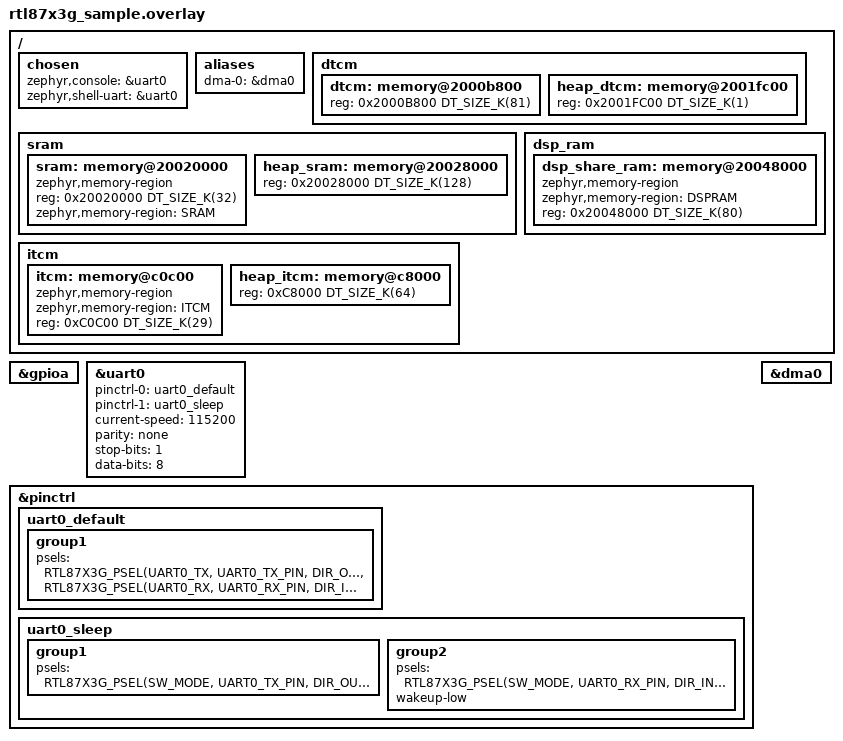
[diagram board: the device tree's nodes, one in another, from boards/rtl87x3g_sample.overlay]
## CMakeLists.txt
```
#
# Copyright (c) 2026, Realtek Semiconductor Corporation
#
# SPDX-License-Identifier: LicenseRef-Realtek-5-Clause
#

message(STATUS "CMAKELIST FOLDER: ${CMAKE_CURRENT_SOURCE_DIR}")

cmake_minimum_required(VERSION 3.20.0)

#===========version generation===========
include(${CMAKE_CURRENT_SOURCE_DIR}/../../cmake/version_generate.cmake)
generate_version()
#===========version generation===========
#===========post build===========
# post build should be called before find_package
include(${CMAKE_CURRENT_SOURCE_DIR}/../../cmake/post_build.cmake)
rtk_post_build()
#===========post build===========

find_package(Zephyr REQUIRED HINTS $ENV{ZEPHYR_BASE})
project(lea_cap_acceptor)

FILE(GLOB app_sources src/*.c)
target_sources(app PRIVATE
  ${app_sources}
  )

set(sources 
   ${ZEPHYR_REALTEK_APP_MODULE_DIR}/subsys/bluetooth/gatt_client/bt_ext_ftl.c
   ${ZEPHYR_REALTEK_APP_MODULE_DIR}/subsys/bluetooth/gatt_client/gattc_tbl_storage.c
   )
   
set(headers 
    #header files from app
	src/
    #header files from libs
    ${ZEPHYR_REALTEK_APP_MODULE_DIR}/subsys/bluetooth/gatt_client
    )

foreach(header ${headers})
    if(EXISTS ${header})
        zephyr_include_directories(${header})
    else()
        message(FATAL_ERROR "header file directory does not exist: ${header}. Current cmakelist: ${CMAKE_CURRENT_SOURCE_DIR}")
    endif()
endforeach()

foreach(src ${sources})
    if(EXISTS ${src})
        target_sources(app PRIVATE ${src})
    else()
        message(FATAL_ERROR "source file does not exist: ${src}. Current cmakelist: ${CMAKE_CURRENT_SOURCE_DIR}")
    endif()
endforeach()

target_precompile_headers(app PUBLIC 
	          ${CMAKE_CURRENT_SOURCE_DIR}/src/app_lea_cap_acc_flags.h
			  )
    
target_include_directories(app PRIVATE src)
```

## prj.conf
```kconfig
# nothing here
CONFIG_REALTEK_SUBSYS_BLE_MGR=y
CONFIG_REALTEK_SUBSYS_SYSM=y
CONFIG_REALTEK_SUBSYS_BLE_AUDIO=y

# Network shell
CONFIG_SERIAL=y
CONFIG_UART_CONSOLE=y
CONFIG_UART_INTERRUPT_DRIVEN=y
CONFIG_UART_ASYNC_API=y
CONFIG_SHELL=y
CONFIG_SHELL_BACKEND_SERIAL=y
CONFIG_LOG_RTK=n
CONFIG_PRINTK=y
CONFIG_HEAP_MEM_POOL_SIZE=1024
CONFIG_CONSOLE=y
#CONFIG_STDOUT_CONSOLE=y

#CONFIG_UART_SHELL_ON_DEV_NAME="UART_2"
#CONFIG_SHELL_PROMPT_UART="uart:~$ "
```

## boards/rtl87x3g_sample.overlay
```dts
/*
 * Copyright(c) 2024, Realtek Semiconductor Corporation.
 *
 * SPDX-License-Identifier: Apache-2.0
 */

#include <zephyr/dt-bindings/gpio/realtek-rtl87x3g-gpio.h>
#include <dt-bindings/pinctrl/rtl87x3g-pinctrl.h>
#include <dt-bindings/input/input-event-codes.h>
#include "../board.h"

&gpioa {
	status = "okay";
};

/ {
    chosen {
        zephyr,console = &uart0;
        zephyr,shell-uart = &uart0;
    };
};

/**
#define GDMA_Handshake_UART0_TX                                     (0)
#define GDMA_Handshake_UART0_RX                                     (1)
#define GDMA_Handshake_UART2_TX                                     (2)
#define GDMA_Handshake_UART2_RX                                     (3)
#define GDMA_Handshake_UART3_TX                                     (48)
#define GDMA_Handshake_UART3_RX                                     (49)
#define GDMA_Handshake_UART4_TX                                     (50)
#define GDMA_Handshake_UART4_RX                                     (51)
#define GDMA_Handshake_UART5_TX                                     (52)
#define GDMA_Handshake_UART5_RX                                     (53)
*/

&uart0 {
	pinctrl-0 = <&uart0_default>;
	pinctrl-1 = <&uart0_sleep>;
	pinctrl-names = "default", "sleep";
	status = "okay";
	current-speed = <115200>;
	parity = "none";
	stop-bits = "1";
	data-bits = <8>;
	//dmas = <&dma0 2 3 0xa>, <&dma0 3 2 0x10021>;
	//dma-names = "rx", "tx";
};

&pinctrl
{
	uart0_default:uart0_default {
		group1 {
			psels = <RTL87X3G_PSEL(UART0_TX, UART0_TX_PIN, DIR_OUT, DRV_HIGH, PULL_UP)>,
			<RTL87X3G_PSEL(UART0_RX, UART0_RX_PIN, DIR_IN, DRV_HIGH, PULL_UP)>;
		};
	};

	uart0_sleep:uart0_sleep {
		group1 {
			psels = <RTL87X3G_PSEL(SW_MODE, UART0_TX_PIN, DIR_OUT, DRV_HIGH, PULL_UP)>;
		};
		group2 {
			psels = <RTL87X3G_PSEL(SW_MODE, UART0_RX_PIN, DIR_IN, DRV_HIGH, PULL_UP)>;
			wakeup-low;
		};
	};
};

&dma0 {
	status = "okay";
};

&gpioa {
	status = "okay";
};

/*delete-node only support nodes with lable */
/delete-node/ &dtcm;
/delete-node/ &heap_dtcm;
/delete-node/ &sram;
/delete-node/ &heap_sram;
/delete-node/ &itcm;
/delete-node/ &heap_itcm;
/delete-node/ &dsp_share_ram;

/ {
	aliases {
		dma-0 = &dma0;
    };

	/* DTCM addr: 0x20000000~0x20020000, total size: 128KByte.
	 * The front 46Kbyte was taken by RTK internal.
	 * If users wants to increase global variables and zephyr static heap,
	 * please follow the steps:
	 * 1. increase dtcm size value "reg = <0x2000B800 DT_SIZE_K(NEW_SIZE)>"
	 * 2. modify heap_dtcm addr label "heap_dtcm: memory@NEW_ADDR"
	 * 3. modify heap_dtcm reg addr "reg = <NEW_ADDR DT_SIZE_K(NEW_SIZE)>"
	 * 4. decrease heap_dtcm size value "reg = <NEW_ADDR DT_SIZE_K(NEW_SIZE)>"
	 * Warning:
	 * 1. the dtcm address should NOT modified!
	 * 2. the dtcm plus heap_dtcm size should NOT exceed 82KByte!
	 */
	dtcm {
		dtcm: memory@2000b800 {
			device_type = "dtcm region";
			reg = <0x2000B800 DT_SIZE_K(81)>;
		};
		heap_dtcm: memory@2001fc00 {
			device_type = "heap dtcm region";
			reg = <0x2001FC00 DT_SIZE_K(1)>;
		};
	};
	/* sram addr: 0x20020000~0x20048000, total size: 160KByte.
	 * call zephyr_code_relocate(FILES xxx.x LOCATION SRAM) at cmakelist could relocate variables on sram.
	 * for more information, please refer to https://docs.zephyrproject.org/latest/kernel/code-relocation.html
	 * If users wants to increase sram size, please follow the steps:
	 * 1. increase sram size value "reg = <0x20020000 DT_SIZE_K(NEW_SIZE)>"
	 * 2. modify heap_sram addr label "heap_sram: memory@NEW_ADDR"
	 * 3. modify heap_sram reg addr "reg = <NEW_ADDR DT_SIZE_K(NEW_SIZE)>"
	 * 4. decrease heap_sram size value "reg = <NEW_ADDR DT_SIZE_K(NEW_SIZE)>"
	 * Warning:
	 * 1. the sram address should NOT modified!
	 * 2. the sram plus heap_sram size should NOT exceed 160KByte!
	 */
	sram {
		sram: memory@20020000 {
			device_type = "sram region";
			compatible = "zephyr,memory-region", "mmio-sram";
			reg = <0x20020000 DT_SIZE_K(32)>;
			zephyr,memory-region = "SRAM";
		};
		heap_sram: memory@20028000 {
			device_type = "heap sram region";
			reg = <0x20028000 DT_SIZE_K(128)>;
		};
	};

	itcm {
		itcm: memory@c0c00 {
			device_type = "itcm region";
			compatible = "zephyr,memory-region", "arm,itcm";
			zephyr,memory-region = "ITCM";
			reg = <0xC0C00 DT_SIZE_K(29)>;
		};
		heap_itcm: memory@c8000 {
			device_type = "heap itcm region";
			reg = <0xC8000 DT_SIZE_K(64)>;
		};
	};

	dsp_ram {
		dsp_share_ram: memory@20048000 {
			compatible = "zephyr,memory-region";
			device_type = "dsp_share_ram region";
			zephyr,memory-region = "DSPRAM";
			reg = <0x20048000 DT_SIZE_K(80)>;
		};
	};

};
```

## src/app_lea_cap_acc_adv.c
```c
/*
 * Copyright (c) 2026, Realtek Semiconductor Corporation
 *
 * SPDX-License-Identifier: LicenseRef-Realtek-5-Clause
 */

/*============================================================================*
 *                              Header Files
 *============================================================================*/
#include <string.h>
#include "trace.h"
#include "gatt.h"
#include "app_shell_cmd.h"
#include "ble_ext_adv.h"
#include "app_lea_cap_acc_adv.h"
#include "app_lea_cap_acc_main.h"
#include "csis_def.h"
#include "csis_rsi.h"
#include "ascs_def.h"
#include "cap.h"
#include "bass_def.h"

#define LE_EXT_TEST_ADV_DATA_LEN                    100

uint8_t app_ext_adv_handle;

uint16_t le_ext_adv_len = 3;
uint16_t le_ext_adv_flag = 0;

uint8_t ext_adv_data[LE_EXT_TEST_ADV_DATA_LEN] =
{
    /* Flags */
    0x02,             /* length */
    GAP_ADTYPE_FLAGS, /* type="Flags" */
    GAP_ADTYPE_FLAGS_LIMITED | GAP_ADTYPE_FLAGS_BREDR_NOT_SUPPORTED,
    //GAP_ADTYPE_FLAGS_LIMITED | GAP_ADTYPE_FLAGS_SIMULTANEOUS_LE_BREDR_CONTROLLER |GAP_ADTYPE_FLAGS_SIMULTANEOUS_LE_BREDR_HOST,
    /* Local name */
    0x07,             /* length */
    GAP_ADTYPE_SERVICE_DATA,
    LO_WORD(GATT_UUID_ASCS),
    HI_WORD(GATT_UUID_ASCS),
    0, 0, 0, 0
};

const uint8_t scan_response_data[] =
{
    /* Local name */
    0x0A,
    GAP_ADTYPE_LOCAL_NAME_COMPLETE,
    'B', 'L', 'E', '_', 'A', 'u', 'd', 'i', 'o',
    0x03,
    GAP_ADTYPE_APPEARANCE,
    LO_WORD(GAP_GATT_APPEARANCE_GENERIC_MEDIA_PLAYER),
    HI_WORD(GAP_GATT_APPEARANCE_GENERIC_MEDIA_PLAYER),
};

#if CSIP_SET_MEMBER
static void app_ext_adv_gen_rsi(uint8_t *p_sirk)
{
    uint8_t psri_data[CSI_RSI_LEN];
    if (csis_gen_rsi(p_sirk, psri_data))
    {
        uint16_t idx = le_ext_adv_len;
        ext_adv_data[idx] = CSI_RSI_LEN + 1;
        idx++;
        ext_adv_data[idx] = GAP_ADTYPE_RSI;
        idx++;
        memcpy(ext_adv_data + idx, psri_data, CSI_RSI_LEN);
        idx += CSI_RSI_LEN;
        le_ext_adv_len = idx;
    }
}
#endif

static bool app_ext_adv_gen_ascs_data(uint8_t *p_data, uint8_t *p_buf_len, uint8_t announcement,
                                      uint8_t meta_data_len, const uint8_t *p_meta_data)
{
    uint8_t idx = 0;
    if (p_data == NULL || p_buf_len == NULL)
    {
        return false;
    }
    if (*p_buf_len < (9 + meta_data_len) ||
        (meta_data_len > 0 && p_meta_data == NULL))
    {
        return false;
    }
    p_data[idx++] = 9 + meta_data_len;
    p_data[idx++] = GAP_ADTYPE_SERVICE_DATA;
    p_data[idx++] = LO_WORD(GATT_UUID_ASCS);
    p_data[idx++] = HI_WORD(GATT_UUID_ASCS);
    p_data[idx++] = announcement;
    LE_UINT16_TO_ARRAY(p_data + idx,
                       app_db.lea_sink_available_contexts);
    idx += 2;
    LE_UINT16_TO_ARRAY(p_data + idx,
                       app_db.lea_source_available_contexts);
    idx += 2;
    p_data[idx++] = meta_data_len;
    if (meta_data_len > 0)
    {
        memcpy(p_data + idx, p_meta_data, meta_data_len);
        idx += meta_data_len;
    }
    *p_buf_len = idx;
    return true;
}

/*Unicast Server that sent the PDU is available for a general audio use case.
In this specification, a general audio use case means the transmission or reception of Audio Data
that has not been initiated by a higher-layer specification.*/
static void app_ext_adv_data_general_audio(void)
{
    uint16_t idx = le_ext_adv_len;
    APP_PRINT_TRACE1("app_ext_adv_data_general_audio: le_ext_adv_flag 0x%x", le_ext_adv_flag);

    if (le_ext_adv_flag & LE_EXT_ADV_ASCS)
    {
        uint8_t buf_len = LE_EXT_TEST_ADV_DATA_LEN - idx;
        if (app_ext_adv_gen_ascs_data(&ext_adv_data[idx], &buf_len, ADV_GENERAL_ANNOUNCEMENT,
                                      0, NULL))
        {
            idx += buf_len;
        }
    }

    if ((le_ext_adv_flag & LE_EXT_ADV_CAP_GEN) ||
        (le_ext_adv_flag & LE_EXT_ADV_CAP_TARGET))
    {
        ext_adv_data[idx] = 0x04;
        idx++;
        ext_adv_data[idx] = GAP_ADTYPE_SERVICE_DATA;
        idx++;
        ext_adv_data[idx] = LO_WORD(GATT_UUID_CAS);
        idx++;
        ext_adv_data[idx] = HI_WORD(GATT_UUID_CAS);
        idx++;
        if (le_ext_adv_flag & LE_EXT_ADV_CAP_GEN)
        {
            ext_adv_data[idx] = ADV_GENERAL_ANNOUNCEMENT;
            idx++;
        }
        else
        {
            ext_adv_data[idx] = ADV_TARGETED_ANNOUNCEMENT;
            idx++;
        }
    }
#if BAP_SCAN_DELEGATOR
    if (le_ext_adv_flag & LE_EXT_ADV_BASS)
    {
        ext_adv_data[idx] = 0x03;
        idx++;
        ext_adv_data[idx] = GAP_ADTYPE_SERVICE_DATA;
        idx++;
        ext_adv_data[idx] = LO_WORD(GATT_UUID_BASS);
        idx++;
        ext_adv_data[idx] = HI_WORD(GATT_UUID_BASS);
        idx++;
    }
#endif
    le_ext_adv_len = idx;
#if CSIP_SET_MEMBER
    if (le_ext_adv_flag & LE_EXT_ADV_PSRI)
    {
        app_ext_adv_gen_rsi((uint8_t *)app_db.lea_csis_sirk);
    }
#endif

    memcpy(&ext_adv_data[le_ext_adv_len], scan_response_data, sizeof(scan_response_data));
    le_ext_adv_len += sizeof(scan_response_data);
}

void app_ext_adv_adv_cfg(uint16_t flag)
{
    le_ext_adv_flag |= flag;
}

void app_ext_adv_update(void)
{
    app_ext_adv_data_general_audio();
    ble_ext_adv_mgr_set_adv_data(app_ext_adv_handle, le_ext_adv_len, ext_adv_data);
}

T_GAP_CAUSE app_ext_adv_start(void)
{
    return ble_ext_adv_mgr_enable(app_ext_adv_handle, 0);
}

T_GAP_CAUSE app_ext_adv_stop(void)
{
    return ble_ext_adv_mgr_disable(app_ext_adv_handle, 0);
}

static void app_ext_adv_callback(uint8_t cb_type, void *p_cb_data)
{
    T_BLE_EXT_ADV_CB_DATA cb_data;
    memcpy(&cb_data, p_cb_data, sizeof(T_BLE_EXT_ADV_CB_DATA));
    switch (cb_type)
    {
    case BLE_EXT_ADV_STATE_CHANGE:
        {
            APP_PRINT_TRACE4("ble_adv_data_callback: BLE_EXT_ADV_STATE_CHANGE, adv_handle %d, state %d, stop_cause %d, app_cause %d",
                             cb_data.p_ble_state_change->adv_handle,
                             cb_data.p_ble_state_change->state,
                             cb_data.p_ble_state_change->stop_cause,
                             cb_data.p_ble_state_change->app_cause);
        }
        break;

    case BLE_EXT_ADV_SET_CONN_INFO:
        APP_PRINT_TRACE1("app_ble_common_adv_callback: BLE_EXT_ADV_SET_CONN_INFO conn_id 0x%x",
                         cb_data.p_ble_conn_info->conn_id);
        break;

    default:
        break;
    }
    return;
}

bool app_ext_adv_params_init(void)
{
    T_LE_EXT_ADV_EXTENDED_ADV_PROPERTY adv_event_prop = LE_EXT_ADV_EXTENDED_ADV_CONN_UNDIRECTED;
    uint32_t primary_adv_interval_min = DEFAULT_ADVERTISING_INTERVAL_MIN;
    uint32_t primary_adv_interval_max = DEFAULT_ADVERTISING_INTERVAL_MAX;
    T_GAP_REMOTE_ADDR_TYPE peer_address_type = GAP_REMOTE_ADDR_LE_PUBLIC;
    uint8_t peer_address[6] = {0};
    T_GAP_ADV_FILTER_POLICY filter_policy = GAP_ADV_FILTER_ANY;
    T_GAP_LOCAL_ADDR_TYPE own_address_type = GAP_LOCAL_ADDR_LE_PUBLIC;

    app_ext_adv_data_general_audio();

    if (ble_ext_adv_mgr_init_adv_params(&app_ext_adv_handle, adv_event_prop, primary_adv_interval_min,
                                        primary_adv_interval_max, own_address_type, peer_address_type, peer_address,
                                        filter_policy, le_ext_adv_len, ext_adv_data,
                                        0, NULL, NULL) == GAP_CAUSE_SUCCESS)
    {
        ble_ext_adv_mgr_register_callback(app_ext_adv_callback, app_ext_adv_handle);
        return true;
    }
    return false;
}
```

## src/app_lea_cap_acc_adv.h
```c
/*
 * Copyright (c) 2026, Realtek Semiconductor Corporation
 *
 * SPDX-License-Identifier: LicenseRef-Realtek-5-Clause
 */

#ifndef _APP_LEA_CAP_ACC_ADV_H_
#define _APP_LEA_CAP_ACC_ADV_H_

#ifdef  __cplusplus
extern "C" {
#endif      /* __cplusplus */

/** @brief  Default minimum advertising interval when device is discoverable (units of 625us, 160=100ms) */
#define DEFAULT_ADVERTISING_INTERVAL_MIN            0x20
/** @brief  Default Maximum advertising interval */
#define DEFAULT_ADVERTISING_INTERVAL_MAX            0x30

#define LE_EXT_ADV_PSRI       0x0001
#define LE_EXT_ADV_ASCS       0x0002
#define LE_EXT_ADV_BASS       0x0004
#define LE_EXT_ADV_CAP_GEN    0x0008
#define LE_EXT_ADV_CAP_TARGET 0x0010

void app_ext_adv_adv_cfg(uint16_t flag);
bool app_ext_adv_params_init(void);

void app_ext_adv_update(void);
T_GAP_CAUSE app_ext_adv_start(void);
T_GAP_CAUSE app_ext_adv_stop(void);

#ifdef  __cplusplus
}
#endif      /*  __cplusplus */

#endif
```

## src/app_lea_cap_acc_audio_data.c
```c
/*
 * Copyright (c) 2026, Realtek Semiconductor Corporation
 *
 * SPDX-License-Identifier: LicenseRef-Realtek-5-Clause
 */

#include <stdlib.h>
#include "os_queue.h"
#include "trace.h"
#include "gap.h"
#include "gap_iso_data.h"
#include "bt_direct_msg.h"
#include "app_lea_cap_acc_main.h"
#include "app_lea_cap_acc_audio_data.h"
#include "ble_audio_def.h"
#include "codec_qos.h"
#if APP_LEA_INPUT_AUDIO_DATA_TEST
#include "app_timer.h"
#endif

#if APP_LEA_INPUT_AUDIO_DATA_TEST
typedef enum
{
    APP_LEA_SEND_ISO_DATA = 0x00,
} T_APP_LEA_TIMER;

static uint8_t app_lea_timer_idx_send_iso_data = 0;
static uint8_t app_lea_timer_id = 0;

const uint8_t lc3_16_2_encoded_data[40] = {0x46, 0xC2, 0x6C, 0x27, 0x41, 0x23, 0x1E, 0x02, 0xE6, 0x7A, 0x04,
                                           0xAB, 0x54, 0x34, 0xFB, 0x6A, 0x0A, 0x24, 0x02, 0x8A, 0xFA, 0x00,
                                           0x00, 0x39, 0x4F, 0x96, 0x0D, 0x38, 0xA7, 0x57, 0xE2, 0x24, 0x56,
                                           0x5F, 0xF1, 0xCB, 0x97, 0x20, 0xF8, 0x9B
                                          };
const uint8_t lc3_16_2_2c_encoded_data[80] = {0x46, 0xC2, 0x6C, 0x27, 0x41, 0x23, 0x1E, 0x02, 0xE6, 0x7A, 0x04,
                                              0xAB, 0x54, 0x34, 0xFB, 0x6A, 0x0A, 0x24, 0x02, 0x8A, 0xFA, 0x00,
                                              0x00, 0x39, 0x4F, 0x96, 0x0D, 0x38, 0xA7, 0x57, 0xE2, 0x24, 0x56,
                                              0x5F, 0xF1, 0xCB, 0x97, 0x20, 0xF8, 0x9B,
                                              0x46, 0xC2, 0x6C, 0x27, 0x41, 0x23, 0x1E, 0x02, 0xE6, 0x7A, 0x04,
                                              0xAB, 0x54, 0x34, 0xFB, 0x6A, 0x0A, 0x24, 0x02, 0x8A, 0xFA, 0x00,
                                              0x00, 0x39, 0x4F, 0x96, 0x0D, 0x38, 0xA7, 0x57, 0xE2, 0x24, 0x56,
                                              0x5F, 0xF1, 0xCB, 0x97, 0x20, 0xF8, 0x9B
                                             };
const uint8_t lc3_16_1_encoded_data[30] = {0x1D,  0x92,  0xB3,  0x67,  0xDE,  0xF5,  0xD0,  0x46,  0xEB,  0xC7,  0xDD,  0x69,  0x89,  0xD8,
                                           0xEA,  0xD5,  0x42,  0x22,  0x4C,  0xBB,  0x53,  0xF9,  0x0D,  0xED,  0xD8,  0xE5,  0x3C,  0xA0,
                                           0xCA,  0x57
                                          };
void app_lea_test_iso_data_send(void)
{
    T_GAP_CAUSE cause = GAP_CAUSE_SUCCESS;
    T_APP_LEA_ISO_CHANN *p_iso_chann = NULL;

    for (uint8_t i = 0; i < app_db.iso_input_queue.count; i++)
    {
        p_iso_chann = (T_APP_LEA_ISO_CHANN *)os_queue_peek(&app_db.iso_input_queue, i);
        if (p_iso_chann->iso_sdu_len != 0)
        {
            cause = gap_iso_send_data((uint8_t *)p_iso_chann->p_encoded_data,
                                      p_iso_chann->iso_conn_handle,
                                      p_iso_chann->iso_sdu_len,
                                      false, (p_iso_chann->pkt_seq_num * p_iso_chann->sdu_interval),
                                      p_iso_chann->pkt_seq_num);
            if (cause != GAP_CAUSE_SUCCESS)
            {
                goto error;
            }
        }
        p_iso_chann->pkt_seq_num++;
    }
    return;
error:
    APP_PRINT_ERROR1("app_lea_test_iso_data_send: failed, cause 0x%x", cause);
    return;
}

static void app_lea_timer_timeout_cb(uint8_t timer_evt, uint16_t param)
{
    switch (timer_evt)
    {
    case APP_LEA_SEND_ISO_DATA:
        {
            app_lea_test_iso_data_send();
        }
        break;

    default:
        break;
    }
}

static void app_lea_test_start_iso_data_timer(uint32_t timeout_ms)
{
    if (app_lea_timer_id == 0)
    {
        app_timer_reg_cb(app_lea_timer_timeout_cb, &app_lea_timer_id);
    }
    app_start_timer(&app_lea_timer_idx_send_iso_data, "iso_data",
                    app_lea_timer_id, APP_LEA_SEND_ISO_DATA, 0, true,
                    timeout_ms);
}


void app_lea_test_iso_chann_remove(void)
{
    APP_PRINT_INFO1("app_lea_test_iso_chann_remove: iso_input_queue %d",
                    app_db.iso_input_queue.count);
    if (app_db.iso_input_queue.count == 0)
    {
        app_stop_timer(&app_lea_timer_idx_send_iso_data);
    }
}

void app_lea_test_iso_chann_add(T_APP_LEA_ISO_CHANN *p_iso_chann)
{
    uint8_t err_idx = 0;

    codec_max_sdu_len_get(&p_iso_chann->codec_data, &p_iso_chann->iso_sdu_len);
    codec_sdu_interval_get(&p_iso_chann->codec_data, &p_iso_chann->sdu_interval);
    p_iso_chann->pkt_seq_num = 1;

    if (p_iso_chann->codec_data.sample_frequency == SAMPLING_FREQUENCY_CFG_16K)
    {
        if (p_iso_chann->codec_data.frame_duration == FRAME_DURATION_CFG_10_MS)
        {
            if (p_iso_chann->iso_sdu_len == sizeof(lc3_16_2_encoded_data))
            {
                p_iso_chann->p_encoded_data = lc3_16_2_encoded_data;
            }
            else if (p_iso_chann->iso_sdu_len == sizeof(lc3_16_2_2c_encoded_data))
            {
                p_iso_chann->p_encoded_data = lc3_16_2_2c_encoded_data;
            }
            else
            {
                err_idx = 3;
                goto failed;
            }
        }
        else if (p_iso_chann->codec_data.frame_duration == FRAME_DURATION_CFG_7_5_MS)
        {
            if (p_iso_chann->iso_sdu_len == sizeof(lc3_16_1_encoded_data))
            {
                p_iso_chann->p_encoded_data = lc3_16_1_encoded_data;
            }
            else
            {
                err_idx = 4;
                goto failed;
            }
        }
    }
    else
    {
        err_idx = 10;
        goto failed;
    }
    APP_PRINT_INFO2("app_lea_test_iso_chann_add: sdu %d, interval %d", p_iso_chann->iso_sdu_len,
                    p_iso_chann->sdu_interval / 1000);

    app_lea_test_start_iso_data_timer(p_iso_chann->sdu_interval / 1000);

    return;
failed:
    APP_PRINT_ERROR1("app_lea_test_iso_chann_add: failed err_idx %d", err_idx);
    return;
}
#endif

T_APP_LEA_ISO_CHANN *app_lea_find_iso_chann(uint16_t iso_conn_handle, uint8_t direction)
{
    int i;
    T_APP_LEA_ISO_CHANN *p_iso_chann = NULL;
    if (direction == DATA_PATH_INPUT_FLAG)
    {
        for (i = 0; i < app_db.iso_input_queue.count; i++)
        {
            p_iso_chann = (T_APP_LEA_ISO_CHANN *)os_queue_peek(&app_db.iso_input_queue, i);
            if (p_iso_chann->iso_conn_handle == iso_conn_handle)
            {
                return p_iso_chann;
            }
        }
    }
    else
    {
        for (i = 0; i < app_db.iso_output_queue.count; i++)
        {
            p_iso_chann = (T_APP_LEA_ISO_CHANN *)os_queue_peek(&app_db.iso_output_queue, i);
            if (p_iso_chann->iso_conn_handle == iso_conn_handle)
            {
                return p_iso_chann;
            }
        }
    }
    return NULL;
}

T_APP_LEA_ISO_CHANN *app_lea_add_iso_chann(uint16_t iso_conn_handle, uint8_t direction)
{
    T_APP_LEA_ISO_CHANN *p_iso_chann;

    p_iso_chann = app_lea_find_iso_chann(iso_conn_handle, direction);
    if (p_iso_chann)
    {
        return p_iso_chann;
    }
    p_iso_chann = calloc(1, sizeof(T_APP_LEA_ISO_CHANN));
    if (p_iso_chann)
    {
        p_iso_chann->iso_conn_handle = iso_conn_handle;
        p_iso_chann->path_direction = direction;
        if (direction == DATA_PATH_INPUT_FLAG)
        {
            os_queue_in(&app_db.iso_input_queue, p_iso_chann);
        }
        else
        {
            os_queue_in(&app_db.iso_output_queue, p_iso_chann);
        }
        APP_PRINT_INFO2("app_lea_add_iso_chann: iso_conn_handle 0x%x, direction %d",
                        iso_conn_handle, direction);
    }
    return p_iso_chann;
}

static void app_lea_remove_iso_chann(uint16_t iso_conn_handle, uint8_t direction)
{
    int i;
    T_APP_LEA_ISO_CHANN *p_iso_chann = NULL;
    APP_PRINT_INFO2("app_lea_remove_iso_chann: iso_conn_handle 0x%x, direction %d",
                    iso_conn_handle, direction);
    if (direction == DATA_PATH_INPUT_FLAG)
    {
        for (i = 0; i < app_db.iso_input_queue.count; i++)
        {
            p_iso_chann = (T_APP_LEA_ISO_CHANN *)os_queue_peek(&app_db.iso_input_queue, i);
            if (p_iso_chann->iso_conn_handle == iso_conn_handle)
            {
                os_queue_delete(&app_db.iso_input_queue, p_iso_chann);
                free(p_iso_chann);
#if APP_LEA_INPUT_AUDIO_DATA_TEST
                app_lea_test_iso_chann_remove();
#endif
                return;
            }
        }
    }
    else
    {
        for (i = 0; i < app_db.iso_output_queue.count; i++)
        {
            p_iso_chann = (T_APP_LEA_ISO_CHANN *)os_queue_peek(&app_db.iso_output_queue, i);
            if (p_iso_chann->iso_conn_handle == iso_conn_handle)
            {
                os_queue_delete(&app_db.iso_output_queue, p_iso_chann);
                free(p_iso_chann);
                return;
            }
        }
    }
}


void app_lea_handle_data_path_setup(T_LEA_SETUP_DATA_PATH *p_data)
{
    T_APP_LEA_ISO_CHANN *p_iso_chann = app_lea_find_iso_chann(p_data->iso_conn_handle,
                                                              p_data->path_direction);
    uint8_t chnl_cnt;
    uint8_t blocks_num = 1;

    if (p_iso_chann != NULL)
    {
        APP_PRINT_WARN0("app_lea_handle_data_path_setup: iso channel already exist");
        return;
    }
    else
    {
        p_iso_chann = app_lea_add_iso_chann(p_data->iso_conn_handle,
                                            p_data->path_direction);
        if (p_iso_chann == NULL)
        {
            return;
        }
        p_iso_chann->iso_mode = p_data->iso_mode;
    }
    p_iso_chann->codec_data = p_data->codec_parsed_data;
    p_iso_chann->presentation_delay = p_data->presentation_delay;
    p_iso_chann->pkt_seq_num = 0;
    if (p_iso_chann->codec_data.audio_channel_allocation == AUDIO_LOCATION_MONO)
    {
        chnl_cnt = 1;
    }
    else
    {
        chnl_cnt = __builtin_popcount(p_iso_chann->codec_data.audio_channel_allocation);
    }
    if (p_iso_chann->codec_data.type_exist & CODEC_CFG_TYPE_BLOCKS_PER_SDU_EXIST)
    {
        blocks_num = p_iso_chann->codec_data.codec_frame_blocks_per_sdu;
    }
    p_iso_chann->frame_num = blocks_num * chnl_cnt;

    APP_PRINT_INFO6("app_lea_handle_data_path_setup: cis handle 0x%04x, frame_num %d, "
                    "dir %u, sample_frequency 0x%x, audio_channel_allocation 0x%08x, presentation_delay 0x%x",
                    p_iso_chann->iso_conn_handle, p_iso_chann->frame_num,
                    p_iso_chann->path_direction,
                    p_iso_chann->codec_data.sample_frequency,
                    p_iso_chann->codec_data.audio_channel_allocation,
                    p_iso_chann->presentation_delay);
#if APP_LEA_INPUT_AUDIO_DATA_TEST
    if (p_data->path_direction == DATA_PATH_INPUT_FLAG)
    {
        app_lea_test_iso_chann_add(p_iso_chann);
    }
#endif
}

void app_lea_handle_data_path_remove(T_LEA_REMOVE_DATA_PATH *p_data)
{
    T_APP_LEA_ISO_CHANN *p_iso_chann = app_lea_find_iso_chann(p_data->iso_conn_handle,
                                                              p_data->path_direction);
    if (p_iso_chann != NULL)
    {
        app_lea_remove_iso_chann(p_data->iso_conn_handle, p_data->path_direction);
    }
}

void app_lea_data_direct_cb(uint8_t cb_type, void *p_cb_data)
{
    T_BT_DIRECT_CB_DATA *p_data = (T_BT_DIRECT_CB_DATA *)p_cb_data;

    switch (cb_type)
    {
    case BT_DIRECT_MSG_ISO_DATA_IND:
        {
#if 0
            APP_PRINT_TRACE5("app_lea_data_direct_cb: conn_handle 0x%x, iso_sdu_len %d, pkt_seq_num 0x%x, time_stamp 0x%x, pkt_status_flag 0x%x",
                             p_data->p_bt_direct_iso->conn_handle, p_data->p_bt_direct_iso->iso_sdu_len,
                             p_data->p_bt_direct_iso->pkt_seq_num, p_data->p_bt_direct_iso->time_stamp,
                             p_data->p_bt_direct_iso->pkt_status_flag);
#endif
#if 0
            uint8_t *p_iso_data = p_data->p_bt_direct_iso->p_buf + p_data->p_bt_direct_iso->offset;
            APP_PRINT_INFO5("app_audio_data_direct_callback: BT_DIRECT_MSG_ISO_DATA_IND, iso_sdu_len 0x%x, p_buf %p, offset %d, p_data %p, data %b",
                            p_data->p_bt_direct_iso->iso_sdu_len, p_data->p_bt_direct_iso->p_buf,
                            p_data->p_bt_direct_iso->offset, p_iso_data, TRACE_BINARY(p_data->p_bt_direct_iso->iso_sdu_len,
                                                                                      p_iso_data));
#endif

            if (p_data->p_bt_direct_iso->pkt_status_flag != ISOCH_DATA_PKT_STATUS_VALID_DATA)
            {
                gap_iso_data_cfm(p_data->p_bt_direct_iso->p_buf);
                break;
            }

            T_APP_LEA_ISO_CHANN *p_iso_chann = app_lea_find_iso_chann(p_data->p_bt_direct_iso->conn_handle,
                                                                      DATA_PATH_OUTPUT_FLAG);
            if (p_iso_chann != NULL)
            {
#if 0
                //Just for sample. Application can send the data to DSP.
                uint16_t written_len;
                T_AUDIO_STREAM_STATUS status;

                if (p_data->p_bt_direct_iso->iso_sdu_len != 0)
                {
                    status = AUDIO_STREAM_STATUS_CORRECT;
                }
                else
                {
                    status = AUDIO_STREAM_STATUS_LOST;
                }
                audio_track_write(handle, p_data->p_bt_direct_iso->time_stamp,
                                  p_data->p_bt_direct_iso->pkt_seq_num,
                                  status,
                                  p_iso_chann->frame_num,
                                  p_data->p_bt_direct_iso->p_buf + p_data->p_bt_direct_iso->offset,
                                  p_data->p_bt_direct_iso->iso_sdu_len,
                                  &written_len);
#endif
            }

            gap_iso_data_cfm(p_data->p_bt_direct_iso->p_buf);
        }
        break;

    default:
        APP_PRINT_ERROR1("app_lea_data_direct_cb: unhandled cb_type 0x%x", cb_type);
        break;
    }
}

void app_lea_audio_data_init(void)
{
    os_queue_init(&app_db.iso_input_queue);
    os_queue_init(&app_db.iso_output_queue);
    gap_register_direct_cb(app_lea_data_direct_cb);
}
```

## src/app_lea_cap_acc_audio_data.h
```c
/*
 * Copyright (c) 2026, Realtek Semiconductor Corporation
 *
 * SPDX-License-Identifier: LicenseRef-Realtek-5-Clause
 */

#ifndef _APP_LEA_CAP_ACC_AUDIO_DATA_H_
#define _APP_LEA_CAP_ACC_AUDIO_DATA_H_

#ifdef  __cplusplus
extern "C" {
#endif      /* __cplusplus */

#include "codec_def.h"
#include "ble_isoch_def.h"

#define CIG_ISO_MODE        0x01
#define BIG_ISO_MODE        0x02

typedef struct t_lea_iso_chann
{
    struct t_lea_iso_chann     *p_next;
    uint8_t                     iso_mode;
    uint8_t                     frame_num;
    uint8_t                     path_direction;   //DATA_PATH_INPUT_FLAG or DATA_PATH_OUTPUT_FLAG
    uint16_t                    iso_conn_handle;
    uint16_t                    pkt_seq_num;
    uint32_t                    presentation_delay;
    T_CODEC_CFG                 codec_data;
#if APP_LEA_INPUT_AUDIO_DATA_TEST
    uint16_t                    iso_sdu_len;
    uint32_t                    sdu_interval;
    const uint8_t              *p_encoded_data;
#endif
} T_APP_LEA_ISO_CHANN;

typedef struct
{
    uint8_t iso_mode;
    uint8_t path_direction;//DATA_PATH_INPUT_FLAG or DATA_PATH_OUTPUT_FLAG
    uint16_t iso_conn_handle;
    uint32_t presentation_delay;
    T_CODEC_CFG codec_parsed_data;
} T_LEA_SETUP_DATA_PATH;

typedef struct
{
    uint8_t iso_mode;
    uint8_t path_direction;//DATA_PATH_INPUT_FLAG or DATA_PATH_OUTPUT_FLAG
    uint16_t iso_conn_handle;
} T_LEA_REMOVE_DATA_PATH;

void app_lea_handle_data_path_setup(T_LEA_SETUP_DATA_PATH *p_data);
void app_lea_handle_data_path_remove(T_LEA_REMOVE_DATA_PATH *p_data);
T_APP_LEA_ISO_CHANN *app_lea_find_iso_chann(uint16_t iso_conn_handle, uint8_t direction);
void app_lea_audio_data_init(void);

#ifdef  __cplusplus
}
#endif      /*  __cplusplus */

#endif
```

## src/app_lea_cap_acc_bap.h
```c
/*
 * Copyright (c) 2026, Realtek Semiconductor Corporation
 *
 * SPDX-License-Identifier: LicenseRef-Realtek-5-Clause
 */

#ifndef _APP_LEA_CAP_ACC_BAP_H_
#define _APP_LEA_CAP_ACC_BAP_H_

#ifdef  __cplusplus
extern "C" {
#endif      /* __cplusplus */

#include "ble_audio_sync.h"
#include "ble_audio.h"
#include "app_lea_cap_acc_scan.h"

#if (BAP_BROADCAST_SINK || BAP_SCAN_DELEGATOR)
#define APP_LEA_BIG_PROC_BIG_SYNC_REQ         0x01
#define APP_LEA_BIG_PROC_BIG_INFO_RECEIVED    0x02
#define APP_LEA_BIG_PROC_BROADCAST_CODE_EXIST 0x04

#define APP_BIG_SYNC_MAX_BIS_NUM              2

typedef struct t_lea_sync_info
{
    struct t_lea_sync_info            *p_next;
    T_BLE_AUDIO_SYNC_HANDLE            sync_handle;

    uint8_t                            source_id;
    T_GAP_PA_SYNC_STATE                pa_state;
    T_GAP_BIG_SYNC_RECEIVER_SYNC_STATE big_state;
#if BAP_BROADCAST_SINK
    uint32_t                           supported_bis_array;
    uint8_t                            big_proc_flags;
    uint8_t                            encryption;
    uint8_t                            broadcast_code[16];
    uint8_t                            bis_num;
    uint8_t                            bis_idx[APP_BIG_SYNC_MAX_BIS_NUM];
#endif
} T_APP_LEA_SYNC_INFO;
#endif

void app_lea_acc_bap_init(void);

void app_lea_acc_bap_update_available_contexts(uint16_t lea_sink_available_contexts,
                                               uint16_t lea_source_available_contexts);

#if (BAP_BROADCAST_SINK || BAP_SCAN_DELEGATOR)
T_APP_LEA_SYNC_INFO *app_lea_add_sync_handle(T_BLE_AUDIO_SYNC_HANDLE sync_handle);
T_APP_LEA_SYNC_INFO *app_lea_find_sync_handle(T_BLE_AUDIO_SYNC_HANDLE sync_handle);
void app_lea_remove_sync(T_BLE_AUDIO_SYNC_HANDLE sync_handle);
bool app_lea_big_terminate(T_APP_LEA_SYNC_INFO *p_sync_info);
bool app_lea_pa_terminate(T_APP_LEA_SYNC_INFO *p_sync_info);
bool app_lea_pa_sync(T_APP_LEA_SYNC_INFO *p_sync_info);
bool app_lea_pa_sync_by_dev_info(T_APP_LEA_BAAS_DEV_INFO *p_dev_info);
void app_lea_big_sync(T_APP_LEA_SYNC_INFO *p_sync_info);
#endif

#ifdef  __cplusplus
}
#endif      /*  __cplusplus */

#endif
```

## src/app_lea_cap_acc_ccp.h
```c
/*
 * Copyright (c) 2026, Realtek Semiconductor Corporation
 *
 * SPDX-License-Identifier: LicenseRef-Realtek-5-Clause
 */

#ifndef _APP_LEA_CAP_ACC_CCP_H_
#define _APP_LEA_CAP_ACC_CCP_H_

#ifdef  __cplusplus
extern "C" {
#endif      /* __cplusplus */

#include "ble_audio.h"
#include "cap.h"
#include "app_lea_cap_acc_link.h"

#if CCP_CALL_CONTROL_CLIENT
typedef struct
{
    uint16_t conn_handle;
    uint8_t  ccid;
    uint8_t  call_index;
} T_APP_LEA_CCP_CALL_DATA;

typedef enum
{
    APP_LEA_CCP_CALL_REJECT = 0x00, /*Incoming call action*/
    APP_LEA_CCP_CALL_ANSWER = 0x01, /*Incoming call action*/
    APP_LEA_CCP_CALL_TERMINATE = 0x02,
    APP_LEA_CCP_CALL_LOCAL_HOLD = 0x03,
    APP_LEA_CCP_CALL_LOCAL_RETRIEVE = 0x04,
} T_APP_LEA_CCP_CALL_ACTION;

void app_lea_acc_ccp_control(T_APP_LEA_CCP_CALL_ACTION action, T_APP_LEA_CCP_CALL_DATA *p_data);
void app_lea_acc_ccp_init_cap(T_CAP_INIT_PARAMS *p_param);
#endif

#ifdef  __cplusplus
}
#endif      /*  __cplusplus */

#endif
```

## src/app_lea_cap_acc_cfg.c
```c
/*
 * Copyright (c) 2026, Realtek Semiconductor Corporation
 *
 * SPDX-License-Identifier: LicenseRef-Realtek-5-Clause
 */

#include "app_lea_cap_acc_cfg.h"
#include "ftl.h"
#include "trace.h"
#include "app_lea_cap_acc_vc_mic.h"

T_APP_CFG_NV app_cfg_nv;

static const T_APP_CFG_NV app_cfg_rw_default =
{
    .hdr.sync_word = DATA_SYNC_WORD,
    .hdr.length = sizeof(T_APP_CFG_NV),
#if VCP_VOLUME_RENDERER
    .lea_vcs_vol_setting = APP_VCS_DEFAULT_VOL_SETTING,
    .lea_vcs_mute = APP_VCS_DEFAULT_MUTE,
    .lea_vcs_change_cnt = APP_VCS_DEFAULT_CHG_CNT,
    .lea_vcs_vol_flag = APP_VCS_DEFAULT_VOL_FLAG,
    .lea_vcs_step_size = APP_VCS_DEFAULT_STEP_SIZE,
#endif
};

uint32_t app_cfg_reset(void)
{
    memcpy(&app_cfg_nv, &app_cfg_rw_default, sizeof(T_APP_CFG_NV));
    return ftl_save_to_storage(&app_cfg_nv, APP_RW_DATA_ADDR, sizeof(T_APP_CFG_NV));
}

static void app_cfg_load(void)
{
    //read-write data
    ftl_load_from_storage(&app_cfg_nv.hdr, APP_RW_DATA_ADDR, sizeof(app_cfg_nv.hdr));

    if (app_cfg_nv.hdr.sync_word != DATA_SYNC_WORD)
    {
        app_cfg_reset();
    }
    else
    {
        uint32_t load_len = app_cfg_nv.hdr.length;

        if (load_len > sizeof(T_APP_CFG_NV))
        {
            APP_PRINT_ERROR0("app_cfg_load, error");
            app_cfg_reset();
        }
        else
        {
            uint32_t res = ftl_load_from_storage(&app_cfg_nv, APP_RW_DATA_ADDR, load_len);

            if (res == 0)
            {
                if (load_len < sizeof(T_APP_CFG_NV))
                {
                    uint8_t *p_dst = ((uint8_t *)&app_cfg_nv) + load_len;
                    uint8_t *p_src = ((uint8_t *)&app_cfg_rw_default) + load_len;

                    memcpy(p_dst, p_src, sizeof(T_APP_CFG_NV) - load_len);
                }
                app_cfg_nv.hdr.length = sizeof(T_APP_CFG_NV);
            }
            else
            {
                app_cfg_reset();
            }
        }
    }
}

uint32_t app_cfg_store_all(void)
{
    return ftl_save_to_storage(&app_cfg_nv, APP_RW_DATA_ADDR, sizeof(T_APP_CFG_NV));
}

void app_cfg_init(void)
{
    app_cfg_load();
}
```

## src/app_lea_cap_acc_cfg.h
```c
/*
 * Copyright (c) 2026, Realtek Semiconductor Corporation
 *
 * SPDX-License-Identifier: LicenseRef-Realtek-5-Clause
 */

#ifndef _APP_LEA_CAP_ACC_CFG_H_
#define _APP_LEA_CAP_ACC_CFG_H_

#include <stdint.h>

#ifdef  __cplusplus
extern "C" {
#endif      /* __cplusplus */

//FTL start
#define APP_RW_DATA_ADDR                    3072

#define DATA_SYNC_WORD                      0xAA55AA55
#define DATA_SYNC_WORD_LEN                  4

/*============================================================================*
 *                              Types
 *============================================================================*/
/** @brief  Read/Write configurations for inbox audio application  */
typedef struct
{
    uint32_t sync_word;
    uint32_t length;
} T_APP_CFG_NV_HDR;

typedef struct
{
    T_APP_CFG_NV_HDR hdr;
#if VCP_VOLUME_RENDERER
    uint8_t lea_vcs_vol_setting;
    uint8_t lea_vcs_mute;
    uint8_t lea_vcs_change_cnt;
    uint8_t lea_vcs_vol_flag;
    uint8_t lea_vcs_step_size;
#endif
} T_APP_CFG_NV;

extern T_APP_CFG_NV app_cfg_nv;

uint32_t app_cfg_store_all(void);
void app_cfg_init(void);

#ifdef  __cplusplus
}
#endif      /*  __cplusplus */

#endif
```

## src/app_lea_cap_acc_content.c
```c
/*
 * Copyright (c) 2026, Realtek Semiconductor Corporation
 *
 * SPDX-License-Identifier: LicenseRef-Realtek-5-Clause
 */

#include "trace.h"
#include <stdlib.h>
#include "app_shell_cmd.h"
#include "mcp_def.h"
#include "ccp_def.h"
#include "app_lea_cap_acc_content.h"
#include "app_lea_cap_acc_main.h"

#if CCP_CALL_CONTROL_CLIENT
T_LEA_CALL_INDEX *app_lea_call_idx_find(T_APP_LEA_CONTENT_DB *p_content,
                                        uint8_t call_index)
{
    T_LEA_CALL_INDEX *p_call;
    if (p_content == NULL)
    {
        return NULL;
    }
    if (p_content->type == APP_LEA_CONTENT_TYPE_TBS)
    {
        for (uint8_t i = 0; i < p_content->param.content_ccp.call_idx_queue.count; i++)
        {
            p_call = (T_LEA_CALL_INDEX *)os_queue_peek(&p_content->param.content_ccp.call_idx_queue, i);
            if (p_call != NULL && p_call->call_index == call_index)
            {
                return p_call;
            }
        }
    }
    return NULL;
}

T_LEA_CALL_INDEX *app_lea_call_idx_add(T_APP_LEA_CONTENT_DB *p_content,
                                       uint8_t call_index, uint8_t call_state, uint8_t call_flags)
{
    T_LEA_CALL_INDEX *p_call;

    if (p_content->type != APP_LEA_CONTENT_TYPE_TBS)
    {
        return NULL;
    }

    p_call = app_lea_call_idx_find(p_content, call_index);
    if (p_call)
    {
        return p_call;
    }
    p_call = calloc(1, sizeof(T_LEA_CALL_INDEX));
    if (p_call)
    {
        p_call->call_index = call_index;
        p_call->call_state = call_state;
        p_call->call_flags = call_flags;
        APP_PRINT_INFO3("app_lea_call_idx_add: call_index 0x%x, call_state %d, call_flags 0x%x",
                        call_index, call_state, call_flags);
        os_queue_in(&p_content->param.content_ccp.call_idx_queue, p_call);
    }
    return p_call;
}

void app_lea_call_idx_del(T_APP_LEA_CONTENT_DB *p_content, uint8_t call_index)
{
    T_LEA_CALL_INDEX *p_call = app_lea_call_idx_find(p_content, call_index);
    if (p_call)
    {
        if (p_call->call_uri != NULL)
        {
            free(p_call->call_uri);
        }
        os_queue_delete(&p_content->param.content_ccp.call_idx_queue, p_call);
        free(p_call);
    }
}
#endif

#if (CCP_CALL_CONTROL_CLIENT || MCP_MEDIA_CONTROL_CLIENT)
#if MCP_MEDIA_CONTROL_CLIENT
void app_lea_media_state_print(uint8_t media_state)
{
    if (media_state == MCS_MEDIA_STATE_INACTIVE)
    {
        app_shell_print("(MCS_MEDIA_STATE_INACTIVE)\r\n");
    }
    else if (media_state == MCS_MEDIA_STATE_PLAYING)
    {
        app_shell_print("(MCS_MEDIA_STATE_PLAYING)\r\n");
    }
    else if (media_state == MCS_MEDIA_STATE_PAUSED)
    {
        app_shell_print("(MCS_MEDIA_STATE_PAUSED)\r\n");
    }
    else if (media_state == MCS_MEDIA_STATE_SEEKING)
    {
        app_shell_print("(MCS_MEDIA_STATE_SEEKING)\r\n");
    }
}
#endif

#if CCP_CALL_CONTROL_CLIENT
void app_lea_call_state_print(uint8_t call_state)
{
    if (call_state == TBS_CALL_STATE_INCOMING)
    {
        app_shell_print("(TBS_CALL_STATE_INCOMING)\r\n");
    }
    else if (call_state == TBS_CALL_STATE_DIALING)
    {
        app_shell_print("(TBS_CALL_STATE_DIALING)\r\n");
    }
    else if (call_state == TBS_CALL_STATE_ALERTING)
    {
        app_shell_print("(TBS_CALL_STATE_ALERTING)\r\n");
    }
    else if (call_state == TBS_CALL_STATE_ACTIVE)
    {
        app_shell_print("(TBS_CALL_STATE_ACTIVE)\r\n");
    }
    else if (call_state == TBS_CALL_STATE_LOCALLY_HELD)
    {
        app_shell_print("(TBS_CALL_STATE_LOCALLY_HELD)\r\n");
    }
    else if (call_state == TBS_CALL_STATE_REMOTELY_HELD)
    {
        app_shell_print("(TBS_CALL_STATE_REMOTELY_HELD)\r\n");
    }
    else if (call_state == TBS_CALL_STATE_LOCALLY_AND_REMOTELY_HELD)
    {
        app_shell_print("(TBS_CALL_STATE_LOCALLY_AND_REMOTELY_HELD)\r\n");
    }
}

#endif

void app_lea_context_print(void)
{
    T_APP_LE_LINK *p_link;
    T_APP_LEA_CONTENT_DB *p_content;

    for (uint8_t i = 0; i < APP_MAX_BLE_LINK_NUM; i++)
    {
        if (app_db.le_link[i].used == true)
        {
            p_link = &app_db.le_link[i];

            app_shell_print("LEA Context: conn handle 0x%4x \r\n", p_link->conn_handle);

            for (uint8_t j = 0; j < p_link->content_queue.count; j++)
            {
                p_content = (T_APP_LEA_CONTENT_DB *)os_queue_peek(&p_link->content_queue, j);
                if (p_content)
                {
#if MCP_MEDIA_CONTROL_CLIENT
                    if (p_content->type == APP_LEA_CONTENT_TYPE_MCS)
                    {
                        app_shell_print("MCS[%d]: general %d, srv_instance_id %d, ccid %d, media_state %d ",
                                        i,  p_content->general, p_content->srv_instance_id,
                                        p_content->ccid, p_content->param.content_mcp.media_state);
                        app_lea_media_state_print(p_content->param.content_mcp.media_state);
                    }
#endif
#if CCP_CALL_CONTROL_CLIENT
                    if (p_content->type == APP_LEA_CONTENT_TYPE_TBS)
                    {
                        app_shell_print("TBS[%d]: general %d, srv_instance_id %d, ccid %d \r\n",
                                        i,  p_content->general, p_content->srv_instance_id, p_content->ccid);
                        for (uint8_t k = 0; k < p_content->param.content_ccp.call_idx_queue.count; k++)
                        {
                            T_LEA_CALL_INDEX *p_call = (T_LEA_CALL_INDEX *)os_queue_peek(
                                                           &p_content->param.content_ccp.call_idx_queue, k);
                            if (p_call != NULL)
                            {
                                app_shell_print("    Call[%d]: call_index %d, call_flags %d, call_uri_len %d, call_state %d ",
                                                k,  p_call->call_index, p_call->call_flags, p_call->call_uri_len, p_call->call_state);
                                app_lea_call_state_print(p_call->call_state);
                            }
                        }
                    }
#endif
                }
            }
        }
    }
}

T_APP_LEA_CONTENT_DB *app_lea_content_find_by_ccid(T_APP_LE_LINK *p_link, uint8_t ccid)
{
    T_APP_LEA_CONTENT_DB *p_content;
    for (uint8_t i = 0; i < p_link->content_queue.count; i++)
    {
        p_content = (T_APP_LEA_CONTENT_DB *)os_queue_peek(&p_link->content_queue, i);
        if (p_content != NULL && p_content->ccid == ccid)
        {
            return p_content;
        }
    }
    return NULL;
}

T_APP_LEA_CONTENT_DB *app_lea_content_find(uint16_t conn_handle, T_APP_LEA_CONTENT_TYPE type,
                                           uint8_t srv_instance_id, bool general)
{
    T_APP_LE_LINK *p_link;
    T_APP_LEA_CONTENT_DB *p_content;

    p_link = app_link_find_le_link_by_conn_handle(conn_handle);
    if (p_link == NULL)
    {
        return NULL;
    }

    for (uint8_t i = 0; i < p_link->content_queue.count; i++)
    {
        p_content = (T_APP_LEA_CONTENT_DB *)os_queue_peek(&p_link->content_queue, i);
        if (p_content != NULL && p_content->type == type &&
            p_content->srv_instance_id == srv_instance_id && p_content->general == general)
        {
            return p_content;
        }
    }
    return NULL;
}

T_APP_LEA_CONTENT_DB *app_lea_content_add(uint16_t conn_handle, T_APP_LEA_CONTENT_TYPE type,
                                          uint8_t srv_instance_id, bool general)
{
    T_APP_LE_LINK *p_link;
    T_APP_LEA_CONTENT_DB *p_content;

    p_link = app_link_find_le_link_by_conn_handle(conn_handle);
    if (p_link == NULL)
    {
        return NULL;
    }

    p_content = app_lea_content_find(conn_handle, type, srv_instance_id, general);
    if (p_content)
    {
        return p_content;
    }
    p_content = calloc(1, sizeof(T_APP_LEA_CONTENT_DB));
    if (p_content)
    {
        p_content->type = type;
        p_content->srv_instance_id = srv_instance_id;
        p_content->general = general;
        APP_PRINT_INFO4("app_lea_content_add: conn_handle 0x%x, type %d, srv_instance_id %d, general %d",
                        p_link->conn_handle, type, srv_instance_id, general);
        os_queue_in(&p_link->content_queue, p_content);
    }
    return p_content;
}

void app_lea_content_free(T_APP_LE_LINK *p_link)
{
    T_APP_LEA_CONTENT_DB *p_content;
    while ((p_content = (T_APP_LEA_CONTENT_DB *)os_queue_out(&p_link->content_queue)) != NULL)
    {
#if CCP_CALL_CONTROL_CLIENT
        if (p_content->type == APP_LEA_CONTENT_TYPE_TBS)
        {
            T_LEA_CALL_INDEX *p_call;
            while ((p_call = (T_LEA_CALL_INDEX *)os_queue_out(&p_content->param.content_ccp.call_idx_queue)) !=
                   NULL)
            {
                if (p_call->call_uri != NULL)
                {
                    free(p_call->call_uri);
                }
                os_queue_delete(&p_content->param.content_ccp.call_idx_queue, p_call);
                free(p_call);
            }
        }
#endif
        free(p_content);
    }
}
#endif
```

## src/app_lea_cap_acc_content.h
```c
/*
 * Copyright (c) 2026, Realtek Semiconductor Corporation
 *
 * SPDX-License-Identifier: LicenseRef-Realtek-5-Clause
 */

#ifndef _APP_LEA_CAP_ACC_CONTENT_H_
#define _APP_LEA_CAP_ACC_CONTENT_H_

#ifdef  __cplusplus
extern "C" {
#endif      /* __cplusplus */

#include "ble_audio.h"
#include "app_lea_cap_acc_link.h"

#if (CCP_CALL_CONTROL_CLIENT || MCP_MEDIA_CONTROL_CLIENT)

typedef enum
{
    APP_LEA_CONTENT_TYPE_MCS        = 0x00,
    APP_LEA_CONTENT_TYPE_TBS        = 0x01,
} T_APP_LEA_CONTENT_TYPE;

#if CCP_CALL_CONTROL_CLIENT
typedef struct t_lea_call_index
{
    struct t_lea_call_index *p_next;
    uint8_t call_index;
    uint8_t call_state;
    uint8_t call_flags;
    uint16_t call_uri_len;
    uint8_t *call_uri;
} T_LEA_CALL_INDEX;

typedef struct
{
    T_OS_QUEUE call_idx_queue;
} T_APP_LEA_CONTENT_CCP;
#endif

#if MCP_MEDIA_CONTROL_CLIENT
typedef struct
{
    uint8_t media_state;
} T_APP_LEA_CONTENT_MCP;
#endif

typedef struct t_app_lea_content_db
{
    struct t_app_lea_content_db *p_next;
    uint8_t                ccid;
    bool                   general;
    bool                   active;
    uint8_t                srv_instance_id;
    T_APP_LEA_CONTENT_TYPE type;
    union
    {
#if MCP_MEDIA_CONTROL_CLIENT
        T_APP_LEA_CONTENT_MCP content_mcp;
#endif
#if CCP_CALL_CONTROL_CLIENT
        T_APP_LEA_CONTENT_CCP content_ccp;
#endif
    } param;
} T_APP_LEA_CONTENT_DB;

void app_lea_media_state_print(uint8_t media_state);
void app_lea_call_state_print(uint8_t call_state);
void app_lea_context_print(void);

T_APP_LEA_CONTENT_DB *app_lea_content_add(uint16_t conn_handle, T_APP_LEA_CONTENT_TYPE type,
                                          uint8_t srv_instance_id, bool general);
T_APP_LEA_CONTENT_DB *app_lea_content_find_by_ccid(T_APP_LE_LINK *p_link, uint8_t ccid);
T_APP_LEA_CONTENT_DB *app_lea_content_find(uint16_t conn_handle, T_APP_LEA_CONTENT_TYPE type,
                                           uint8_t srv_instance_id, bool general);
void app_lea_content_free(T_APP_LE_LINK *p_link);

#if CCP_CALL_CONTROL_CLIENT
T_LEA_CALL_INDEX *app_lea_call_idx_add(T_APP_LEA_CONTENT_DB *p_content, uint8_t call_index,
                                       uint8_t call_state, uint8_t call_flags);
T_LEA_CALL_INDEX *app_lea_call_idx_find(T_APP_LEA_CONTENT_DB *p_content, uint8_t call_index);
void app_lea_call_idx_del(T_APP_LEA_CONTENT_DB *p_content, uint8_t call_index);
#endif
#endif

#ifdef  __cplusplus
}
#endif      /*  __cplusplus */

#endif
```
